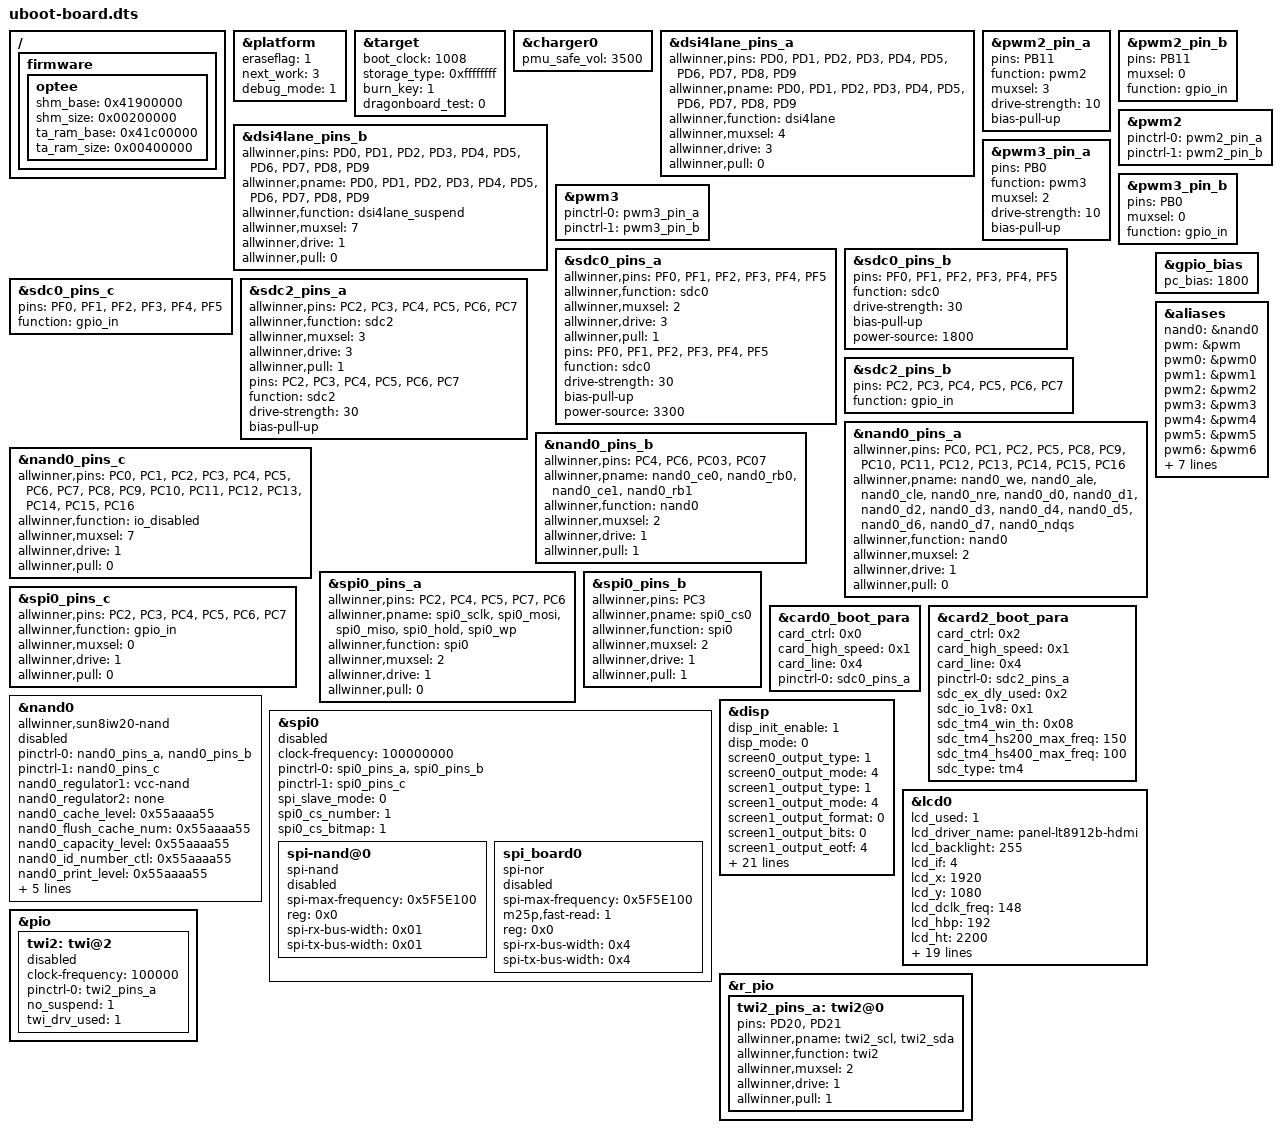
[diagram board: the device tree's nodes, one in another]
/*
 * Allwinner Technology CO., Ltd. sun8iw20p1 soc board.
 *
 * soc board support.
 */
/{
	firmware {
		optee {
			shm_base = <0x41900000>;
			shm_size = <0x00200000>;
			ta_ram_base = <0x41c00000>;
			ta_ram_size = <0x00400000>;
		};
	};
};

&platform {
	eraseflag   = <1>;
	next_work   = <3>;
	debug_mode  = <1>;
};

&target {
	boot_clock = <1008>;	/*CPU boot frequency, Unit: MHz*/
	storage_type = <0xffffffff>; /*boot medium, 0-nand, 1-card0, 2-card2, -1(defualt)auto scan*/
	burn_key = <1>;		/*1:support burn key; 0:not support burn key*/
	dragonboard_test = <0>;	/*1:support card boot dragonboard; 0:not support card boot dragonboard*/
};


&charger0 {
	pmu_safe_vol = <3500>;
};
/*
&rgb18_pins_a {
	allwinner,pins = "PD0", "PD1", "PD2", "PD3", "PD4", "PD5", "PD6", "PD7", "PD8", "PD9", \
	"PD10", "PD11", "PD12", "PD13", "PD14", "PD15", "PD16", "PD17", "PD18", "PD19", \
	"PD20", "PD21";
	allwinner,pname = "PD0", "PD1", "PD2", "PD3", "PD4", "PD5", "PD6", "PD7", "PD8", "PD9", \
	"PD10", "PD11", "PD12", "PD13", "PD14", "PD15", "PD16", "PD17", "PD18", "PD19", \
	"PD20", "PD21";
	allwinner,function = "rgb18";
	allwinner,muxsel = <2>;
	allwinner,drive = <3>;
	allwinner,pull = <0>;
};

&rgb18_pins_b {
	allwinner,pins = "PD0", "PD1", "PD2", "PD3", "PD4", "PD5", "PD6", "PD7", "PD8", "PD9", \
	"PD10", "PD11", "PD12", "PD13", "PD14", "PD15", "PD16", "PD17", "PD18", "PD19", \
	"PD20", "PD21";
	allwinner,pname = "PD0", "PD1", "PD2", "PD3", "PD4", "PD5", "PD6", "PD7", "PD8", "PD9", \
	"PD10", "PD11", "PD12", "PD13", "PD14", "PD15", "PD16", "PD17", "PD18", "PD19", \
	"PD20", "PD21";
	allwinner,function = "rgb18_suspend";
	allwinner,muxsel = <7>;
	allwinner,drive = <1>;
	allwinner,pull = <0>;
};
*/
&dsi4lane_pins_a {
    allwinner,pins = "PD0", "PD1", "PD2", "PD3", "PD4", "PD5", "PD6", "PD7", "PD8", "PD9";
    allwinner,pname = "PD0", "PD1", "PD2", "PD3", "PD4", "PD5", "PD6", "PD7", "PD8", "PD9";
    allwinner,function = "dsi4lane";
    allwinner,muxsel = <4>;
    allwinner,drive = <3>;
    allwinner,pull = <0>;
	};

&dsi4lane_pins_b {
    allwinner,pins = "PD0", "PD1", "PD2", "PD3", "PD4", "PD5", "PD6", "PD7", "PD8", "PD9";
    allwinner,pname = "PD0", "PD1", "PD2", "PD3", "PD4", "PD5", "PD6", "PD7", "PD8", "PD9";
    allwinner,function = "dsi4lane_suspend";
    allwinner,muxsel = <7>;
    allwinner,drive = <1>;
    allwinner,pull = <0>;
};
&pwm2_pin_a {
        pins = "PB11";
        function = "pwm2";
        muxsel = <3>;
        drive-strength = <10>;
        bias-pull-up;
};

&pwm2_pin_b {
        pins = "PB11";
        muxsel = <0>;
        function = "gpio_in";
};

&pwm2 {
        pinctrl-names = "active", "sleep";
        pinctrl-0 = <&pwm2_pin_a>;
        pinctrl-1 = <&pwm2_pin_b>;
        status = "okay";
};
&pwm3_pin_a {
	pins = "PB0";
	function = "pwm3";
	muxsel = <2>;
	drive-strength = <10>;
	bias-pull-up;
};

&pwm3_pin_b {
	pins = "PB0";
	muxsel = <0>;
	function = "gpio_in";
};

&pwm3 {
	pinctrl-names = "active", "sleep";
	pinctrl-0 = <&pwm3_pin_a>;
	pinctrl-1 = <&pwm3_pin_b>;
	status = "okay";
};

&sdc0_pins_a {
	allwinner,pins = "PF0", "PF1", "PF2",
			 "PF3", "PF4", "PF5";
	allwinner,function = "sdc0";
	allwinner,muxsel = <2>;
	allwinner,drive = <3>;
	allwinner,pull = <1>;
	pins = "PF0", "PF1", "PF2",
	       "PF3", "PF4", "PF5";
	function = "sdc0";
	drive-strength = <30>;
	bias-pull-up;
	power-source = <3300>;
};

&sdc0_pins_b {
	pins = "PF0", "PF1", "PF2",
	       "PF3", "PF4", "PF5";
	function = "sdc0";
	drive-strength = <30>;
	bias-pull-up;
	power-source = <1800>;
};

&sdc0_pins_c {
		pins = "PF0", "PF1", "PF2",
			"PF3", "PF4", "PF5";
		function = "gpio_in";

};


&sdc2_pins_a {
	allwinner,pins = "PC2", "PC3", "PC4",
			 "PC5", "PC6", "PC7";
	allwinner,function = "sdc2";
	allwinner,muxsel = <3>;
	allwinner,drive = <3>;
	allwinner,pull = <1>;
	pins = "PC2", "PC3", "PC4",
		"PC5", "PC6", "PC7";
	function = "sdc2";
	drive-strength = <30>;
	bias-pull-up;

};

&sdc2_pins_b {
	pins = "PC2", "PC3", "PC4",
	       "PC5", "PC6", "PC7";
	function = "gpio_in";
};



&nand0_pins_a {
	allwinner,pins = "PC0", "PC1", "PC2", "PC5",
			 "PC8", "PC9", "PC10", "PC11",
			 "PC12", "PC13", "PC14", "PC15",
			 "PC16";
	allwinner,pname= "nand0_we", "nand0_ale","nand0_cle", "nand0_nre",
			 "nand0_d0", "nand0_d1", "nand0_d2", "nand0_d3",
			 "nand0_d4", "nand0_d5", "nand0_d6", "nand0_d7",
			 "nand0_ndqs";
	allwinner,function = "nand0";
	allwinner,muxsel = <2>;
	allwinner,drive = <1>;
	allwinner,pull = <0>;
};

&nand0_pins_b {
	allwinner,pins = "PC4", "PC6", "PC03", "PC07";
	allwinner,pname= "nand0_ce0", "nand0_rb0", "nand0_ce1", "nand0_rb1";
	allwinner,function = "nand0";
	allwinner,muxsel = <2>;
	allwinner,drive = <1>;
	allwinner,pull = <1>;	/* only RB&CE should be pulled up */
};

&nand0_pins_c {
	allwinner,pins = "PC0", "PC1", "PC2", "PC3",
			 "PC4", "PC5", "PC6", "PC7",
			 "PC8", "PC9", "PC10", "PC11",
			 "PC12", "PC13", "PC14", "PC15",
			 "PC16";
	allwinner,function = "io_disabled";
	allwinner,muxsel = <7>;
	allwinner,drive = <1>;
	allwinner,pull = <0>;
};

&spi0_pins_a {
	allwinner,pins = "PC2", "PC4", "PC5",
			"PC7", "PC6";
	allwinner,pname = "spi0_sclk", "spi0_mosi",
			"spi0_miso", "spi0_hold", "spi0_wp";
	allwinner,function = "spi0";
	allwinner,muxsel = <2>;
	allwinner,drive = <1>;
	allwinner,pull = <0>;
};

&spi0_pins_b {
	allwinner,pins = "PC3";
	allwinner,pname = "spi0_cs0";
	allwinner,function = "spi0";
	allwinner,muxsel = <2>;
	allwinner,drive = <1>;
	allwinner,pull = <1>;   // only CS should be pulled up
};

&spi0_pins_c {
	allwinner,pins = "PC2", "PC3", "PC4", "PC5",
			"PC6", "PC7";
	allwinner,function = "gpio_in";
	allwinner,muxsel = <0>;
	allwinner,drive = <1>;
	allwinner,pull = <0>;
};

&card0_boot_para {  /* Avoid dtc compiling warnings. @TODO: Developer should modify this to the actual value */
	/* reg = <0x0 0x2 0x0 0x0>;  [> Avoid dtc compiling warnings. @TODO: Developer should modify this to the actual value <] */
	device_type = "card0_boot_para";
	card_ctrl = <0x0>;
	card_high_speed = <0x1>;
	card_line = <0x4>;
	pinctrl-0 = <&sdc0_pins_a>;
};

&card2_boot_para {  /* Avoid dtc compiling warnings. @TODO: Developer should modify this to the actual value */
	/* reg = <0x0 0x3 0x0 0x0>;  [> Avoid dtc compiling warnings. @TODO: Developer should modify this to the actual value <] */
	device_type = "card2_boot_para";
	card_ctrl = <0x2>;
	card_high_speed = <0x1>;
	card_line = <0x4>;
	pinctrl-0 = <&sdc2_pins_a>;
	sdc_ex_dly_used = <0x2>;
	sdc_io_1v8 = <0x1>;
	sdc_tm4_win_th = <0x08>;
	sdc_tm4_hs200_max_freq = <150>;
	sdc_tm4_hs400_max_freq = <100>;
	sdc_type = "tm4";
};
&gpio_bias {  /* Avoid dtc compiling warnings. @TODO: Developer should modify this to the actual value */
	device_type = "gpio_bias";
	pc_bias = <1800>;
};

&nand0 {
	compatible = "allwinner,sun8iw20-nand";
	device_type = "nand0";
	//reg = <0x0 0x04011000 0x0 0x1000>;/* nand0 */
	pinctrl-names = "default", "sleep";
	pinctrl-0 = <&nand0_pins_a &nand0_pins_b>;
	pinctrl-1 = <&nand0_pins_c>;
	nand0_regulator1 = "vcc-nand";
	nand0_regulator2 = "none";
	nand0_cache_level = <0x55aaaa55>;
	nand0_flush_cache_num = <0x55aaaa55>;
	nand0_capacity_level = <0x55aaaa55>;
	nand0_id_number_ctl = <0x55aaaa55>;
	nand0_print_level = <0x55aaaa55>;
	nand0_p0 = <0x55aaaa55>;
	nand0_p1 = <0x55aaaa55>;
	nand0_p2 = <0x55aaaa55>;
	nand0_p3 = <0x55aaaa55>;
	chip_code = "sun8iw20";
	status = "disabled";
};

&spi0 {
	clock-frequency = <100000000>;
	pinctrl-0 = <&spi0_pins_a &spi0_pins_b>;
	pinctrl-1 = <&spi0_pins_c>;
	pinctrl-names = "default", "sleep";
	/*spi-supply = <&reg_dcdc1>;*/
	spi_slave_mode = <0>;
	spi0_cs_number = <1>;
	spi0_cs_bitmap = <1>;
	status = "disabled";

	spi-nand@0 {
		compatible = "spi-nand";
		spi-max-frequency=<0x5F5E100>;
		reg = <0x0>;
		spi-rx-bus-width=<0x01>;
		spi-tx-bus-width=<0x01>;
		status="disabled";
	};

	spi_board0 {
		device_type = "spi_board0";
		compatible = "spi-nor";
		spi-max-frequency = <0x5F5E100>;
		m25p,fast-read = <1>;
		reg = <0x0>;
		spi-rx-bus-width = <0x4>;
		spi-tx-bus-width = <0x4>;
		status = "disabled";
	};
};


&disp {
	disp_init_enable         = <1>;
	disp_mode                = <0>;

	screen0_output_type      = <1>;
	screen0_output_mode      = <4>;

	screen1_output_type      = <1>;
	screen1_output_mode      = <4>;

	screen1_output_format    = <0>;
	screen1_output_bits      = <0>;
	screen1_output_eotf      = <4>;
	screen1_output_cs        = <257>;
	screen1_output_range     = <2>;
	screen1_output_scan      = <0>;
	screen1_output_aspect_ratio = <8>;

	dev0_output_type         = <1>;
	dev0_output_mode         = <4>;
	dev0_screen_id           = <0>;
	dev0_do_hpd              = <0>;

	dev1_output_type         = <4>;
	dev1_output_mode         = <10>;
	dev1_screen_id           = <1>;
	dev1_do_hpd              = <1>;

	def_output_dev           = <0>;

	fb0_format               = <0>;
	fb0_width                = <0>;
	fb0_height               = <0>;

	fb1_format               = <0>;
	fb1_width                = <0>;
	fb1_height               = <0>;
	chn_cfg_mode             = <1>;

	disp_para_zone           = <1>;
	/*VCC-LCD*/
/*	dc1sw-supply = <&reg_dc1sw>;*/
	/*VCC-DSI*/
/*	eldo3-supply = <&reg_eldo3>;*/
	/*VCC-PD*/
/*	dcdc1-supply = <&reg_dcdc1>;*/
};


&lcd0 {
        lcd_used            = <1>;

        lcd_driver_name     = "panel-lt8912b-hdmi";
        lcd_backlight       = <255>;
        lcd_if              = <4>;

        lcd_x               = <1920>;
        lcd_y               = <1080>;
        lcd_dclk_freq       = <148>;

        lcd_hbp             = <192>;
        lcd_ht              = <2200>;
        lcd_hspw            = <44>;
        lcd_vbp             = <41>;
        lcd_vt              = <1125>;
        lcd_vspw            = <5>;

        lcd_dsi_lane        = <4>;
        lcd_dsi_if          = <0>;
        lcd_dsi_format      = <0>;
        lcd_dsi_te          = <0>;
        lcd_frm             = <0>;
        lcd_io_phase        = <0>;
        lcd_gamma_en        = <0>;
        lcd_bright_curve_en = <0>;
        lcd_cmap_en         = <0>;

        deu_mode            = <0>;
        lcdgamma4iep        = <22>;
        smart_color         = <90>;

        lcd_gpio_0 = <&pio PE 17 GPIO_ACTIVE_HIGH>;
        pinctrl-0 = <&dsi4lane_pins_a>;
        pinctrl-1 = <&dsi4lane_pins_b>;
};

/*
&pio {
        twi2_pins_a: twi2@0 {
                pins = "PD20", "PD21";
                allwinner,pname = "twi2_scl", "twi2_sda";
                allwinner,function = "twi2";
                allwinner,muxsel = <2>;
                allwinner,drive = <1>;
                allwinner,pull = <1>;
        };
};


&twi2 {
	clock-frequency = <400000>;
	pinctrl-0 = <&twi2_pins_a>;
	no_suspend = <1>;
	twi_drv_used = <1>;
	status = "okay";
};
*/

&r_pio {
        twi2_pins_a: twi2@0 {
                //pins = "PE12", "PE13";
                pins = "PD20", "PD21";
                allwinner,pname = "twi2_scl", "twi2_sda";
                allwinner,function = "twi2";
                allwinner,muxsel = <2>;
                allwinner,drive = <1>;
                allwinner,pull = <1>;
        };
};

&pio {
        twi2: twi@2{
                clock-frequency = <100000>;
                pinctrl-0 = <&twi2_pins_a>;
                no_suspend = <1>;
                twi_drv_used = <1>;
                status = "disabled";
        };
};


&aliases {
	nand0 = &nand0;
	pwm = &pwm;
	pwm0 = &pwm0;
	pwm1 = &pwm1;
	pwm2 = &pwm2;
	pwm3 = &pwm3;
	pwm4 = &pwm4;
	pwm5 = &pwm5;
	pwm6 = &pwm6;
	pwm7 = &pwm7;
	disp = &disp;
	lcd0 = &lcd0;
	lcd1 = &lcd1;
	eink = &eink;
	spi0 = &spi0;
	twi2 = &twi2;
};
